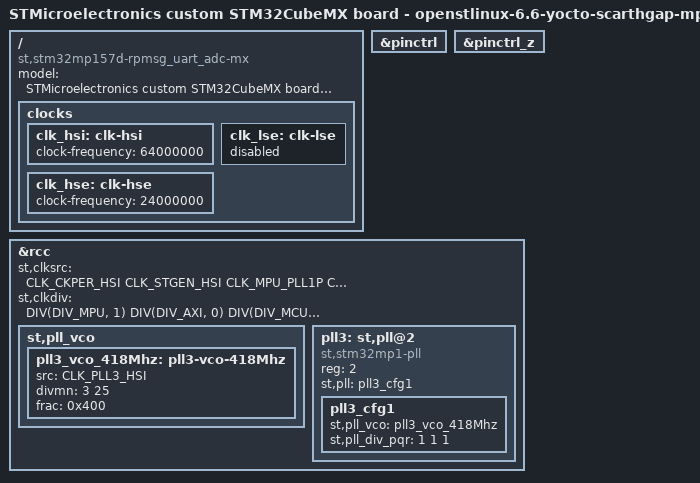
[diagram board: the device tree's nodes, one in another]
// SPDX-License-Identifier: (GPL-2.0-only OR BSD-3-Clause)
/*
 * Copyright (C) 2026, STMicroelectronics - All Rights Reserved
 * Author: STM32CubeMX code generation for STMicroelectronics.
 */

/* For more information on Device Tree configuration, please refer to
 * https://wiki.st.com/stm32mpu/wiki/Category:Device_tree_configuration
 */

/dts-v1/;

#include <dt-bindings/pinctrl/stm32-pinfunc.h>
#include <dt-bindings/clock/stm32mp1-clksrc.h>

#include "stm32mp157.dtsi"
#include "stm32mp15xd.dtsi"
#include "stm32mp15xxaa-pinctrl.dtsi"
/* !!! log : Warning - DDR not configured: unknown DDR dtsi  !!! */
/*#include "???-ddr.dtsi"*/

/* USER CODE BEGIN includes */
/* USER CODE END includes */

/ {
	model = "STMicroelectronics custom STM32CubeMX board - openstlinux-6.6-yocto-scarthgap-mpu-v26.02.18";
	compatible = "st,stm32mp157d-rpmsg_uart_adc-mx", "st,stm32mp157";

	/* !!! log : Warning - no DDR config found: 'memory' node not generated  !!! */

	/*
	memory@??? {
		reg = < ??? >;
	};
	*/

	/* USER CODE BEGIN root */
	/* USER CODE END root */

	clocks {
		/* USER CODE BEGIN clocks */
		/* USER CODE END clocks */

		clk_hsi: clk-hsi {
			clock-frequency = <64000000>;

			/* USER CODE BEGIN clk_hsi */
			/* USER CODE END clk_hsi */
		};
		clk_lse: clk-lse {
			status = "disabled";

			/* USER CODE BEGIN clk_lse */
			/* USER CODE END clk_lse */
		};
		clk_hse: clk-hse {
			clock-frequency = <24000000>;

			/* USER CODE BEGIN clk_hse */
			/* USER CODE END clk_hse */
		};
	};

}; /*root*/

&pinctrl {
	/* USER CODE BEGIN pinctrl */
	/* USER CODE END pinctrl */
};

&pinctrl_z {
	/* USER CODE BEGIN pinctrl_z */
	/* USER CODE END pinctrl_z */
};

&rcc {
	status = "okay";
	/* USER CODE BEGIN rcc */
	/* USER CODE END rcc */
	st,clksrc = <
		CLK_CKPER_HSI
		CLK_STGEN_HSI
		CLK_MPU_PLL1P
		CLK_AXI_HSI
		CLK_MCU_PLL3P
	>;
	st,clkdiv = <
		DIV(DIV_MPU, 1)
		DIV(DIV_AXI, 0)
		DIV(DIV_MCU, 0)
		DIV(DIV_APB1, 1)
		DIV(DIV_APB2, 1)
		DIV(DIV_APB3, 1)
		DIV(DIV_APB4, 0)
		DIV(DIV_APB5, 0)
		DIV(DIV_RTC, 0)
		DIV(DIV_MCO1, 0)
		DIV(DIV_MCO2, 0)
	>;
	st,pll_vco {
		pll3_vco_418Mhz: pll3-vco-418Mhz {
			src = < CLK_PLL3_HSI >;
			divmn = < 3 25 >;
			frac = < 0x400 >;
		};
		/* USER CODE BEGIN rcc_st-pll_vco */
		/* USER CODE END rcc_st-pll_vco */
	};

	pll3:st,pll@2 {
		compatible = "st,stm32mp1-pll";
		reg = <2>;

		st,pll = < &pll3_cfg1 >;

		pll3_cfg1: pll3_cfg1 {
			st,pll_vco = < &pll3_vco_418Mhz >;
			st,pll_div_pqr = < 1 1 1 >;
		};
		/* USER CODE BEGIN pll3 */
		/* USER CODE END pll3 */
	};

};

/* USER CODE BEGIN addons */
/* USER CODE END addons */

